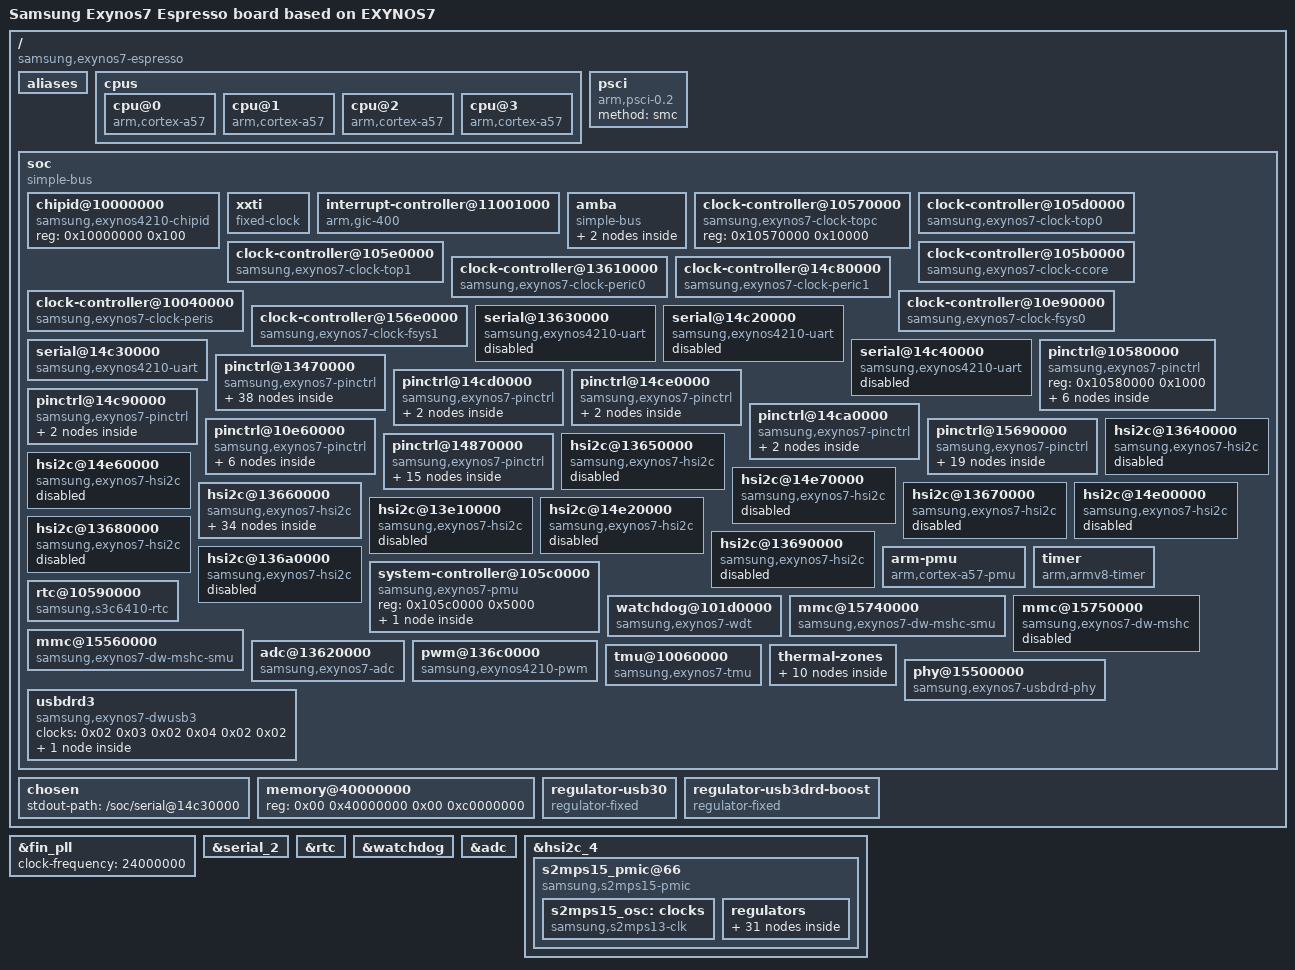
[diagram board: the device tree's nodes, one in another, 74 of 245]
/dts-v1/;

/ {
	compatible = "samsung,exynos7-espresso\0samsung,exynos7";
	interrupt-parent = <0x01>;
	#address-cells = <0x01>;
	#size-cells = <0x01>;
	model = "Samsung Exynos7 Espresso board based on EXYNOS7";

	aliases {
		pinctrl0 = "/soc/pinctrl@10580000";
		pinctrl1 = "/soc/pinctrl@13470000";
		pinctrl2 = "/soc/pinctrl@14cd0000";
		pinctrl3 = "/soc/pinctrl@14ce0000";
		pinctrl4 = "/soc/pinctrl@14c90000";
		pinctrl5 = "/soc/pinctrl@14ca0000";
		pinctrl6 = "/soc/pinctrl@10e60000";
		pinctrl7 = "/soc/pinctrl@15690000";
		pinctrl8 = "/soc/pinctrl@14870000";
		tmuctrl0 = "/soc/tmu@10060000";
		serial0 = "/soc/serial@14c30000";
		mshc0 = "/soc/mmc@15740000";
		mshc2 = "/soc/mmc@15560000";
	};

	cpus {
		#address-cells = <0x01>;
		#size-cells = <0x00>;

		cpu@0 {
			device_type = "cpu";
			compatible = "arm,cortex-a57\0arm,armv8";
			reg = <0x00>;
			enable-method = "psci";
			phandle = <0x17>;
		};

		cpu@1 {
			device_type = "cpu";
			compatible = "arm,cortex-a57\0arm,armv8";
			reg = <0x01>;
			enable-method = "psci";
			phandle = <0x18>;
		};

		cpu@2 {
			device_type = "cpu";
			compatible = "arm,cortex-a57\0arm,armv8";
			reg = <0x02>;
			enable-method = "psci";
			phandle = <0x19>;
		};

		cpu@3 {
			device_type = "cpu";
			compatible = "arm,cortex-a57\0arm,armv8";
			reg = <0x03>;
			enable-method = "psci";
			phandle = <0x1a>;
		};
	};

	psci {
		compatible = "arm,psci-0.2";
		method = "smc";
	};

	soc {
		compatible = "simple-bus";
		#address-cells = <0x01>;
		#size-cells = <0x01>;
		ranges;
		phandle = <0x35>;

		chipid@10000000 {
			compatible = "samsung,exynos4210-chipid";
			reg = <0x10000000 0x100>;
		};

		xxti {
			compatible = "fixed-clock";
			clock-output-names = "fin_pll";
			#clock-cells = <0x00>;
			clock-frequency = <0x16e3600>;
			phandle = <0x03>;
		};

		interrupt-controller@11001000 {
			compatible = "arm,gic-400";
			#interrupt-cells = <0x03>;
			#address-cells = <0x00>;
			interrupt-controller;
			reg = <0x11001000 0x1000 0x11002000 0x1000 0x11004000 0x2000 0x11006000 0x2000>;
			phandle = <0x01>;
		};

		amba {
			compatible = "simple-bus";
			#address-cells = <0x01>;
			#size-cells = <0x01>;
			ranges;

			pdma@10e10000 {
				compatible = "arm,pl330\0arm,primecell";
				reg = <0x10e10000 0x1000>;
				interrupts = <0x00 0xe1 0x04>;
				clocks = <0x02 0x09>;
				clock-names = "apb_pclk";
				#dma-cells = <0x01>;
				#dma-channels = <0x08>;
				#dma-requests = <0x20>;
				phandle = <0x36>;
			};

			pdma@10eb0000 {
				compatible = "arm,pl330\0arm,primecell";
				reg = <0x10eb0000 0x1000>;
				interrupts = <0x00 0xe2 0x04>;
				clocks = <0x02 0x0a>;
				clock-names = "apb_pclk";
				#dma-cells = <0x01>;
				#dma-channels = <0x08>;
				#dma-requests = <0x20>;
				phandle = <0x37>;
			};
		};

		clock-controller@10570000 {
			compatible = "samsung,exynos7-clock-topc";
			reg = <0x10570000 0x10000>;
			#clock-cells = <0x01>;
			phandle = <0x04>;
		};

		clock-controller@105d0000 {
			compatible = "samsung,exynos7-clock-top0";
			reg = <0x105d0000 0xb000>;
			#clock-cells = <0x01>;
			clocks = <0x03 0x04 0x02 0x04 0x03 0x04 0x04 0x04 0x05>;
			clock-names = "fin_pll\0dout_sclk_bus0_pll\0dout_sclk_bus1_pll\0dout_sclk_cc_pll\0dout_sclk_mfc_pll";
			phandle = <0x05>;
		};

		clock-controller@105e0000 {
			compatible = "samsung,exynos7-clock-top1";
			reg = <0x105e0000 0xb000>;
			#clock-cells = <0x01>;
			clocks = <0x03 0x04 0x02 0x04 0x03 0x04 0x04 0x04 0x05>;
			clock-names = "fin_pll\0dout_sclk_bus0_pll\0dout_sclk_bus1_pll\0dout_sclk_cc_pll\0dout_sclk_mfc_pll";
			phandle = <0x06>;
		};

		clock-controller@105b0000 {
			compatible = "samsung,exynos7-clock-ccore";
			reg = <0x105b0000 0xd00>;
			#clock-cells = <0x01>;
			clocks = <0x03 0x04 0x06>;
			clock-names = "fin_pll\0dout_aclk_ccore_133";
			phandle = <0x1c>;
		};

		clock-controller@13610000 {
			compatible = "samsung,exynos7-clock-peric0";
			reg = <0x13610000 0xd00>;
			#clock-cells = <0x01>;
			clocks = <0x03 0x05 0x02 0x05 0x03>;
			clock-names = "fin_pll\0dout_aclk_peric0_66\0sclk_uart0";
			phandle = <0x07>;
		};

		clock-controller@14c80000 {
			compatible = "samsung,exynos7-clock-peric1";
			reg = <0x14c80000 0xd00>;
			#clock-cells = <0x01>;
			clocks = <0x03 0x05 0x01 0x05 0x04 0x05 0x05 0x05 0x06>;
			clock-names = "fin_pll\0dout_aclk_peric1_66\0sclk_uart1\0sclk_uart2\0sclk_uart3";
			phandle = <0x08>;
		};

		clock-controller@10040000 {
			compatible = "samsung,exynos7-clock-peris";
			reg = <0x10040000 0xd00>;
			#clock-cells = <0x01>;
			clocks = <0x03 0x04 0x01>;
			clock-names = "fin_pll\0dout_aclk_peris_66";
			phandle = <0x1e>;
		};

		clock-controller@10e90000 {
			compatible = "samsung,exynos7-clock-fsys0";
			reg = <0x10e90000 0xd00>;
			#clock-cells = <0x01>;
			clocks = <0x03 0x06 0x02 0x06 0x03>;
			clock-names = "fin_pll\0dout_aclk_fsys0_200\0dout_sclk_mmc2";
			phandle = <0x02>;
		};

		clock-controller@156e0000 {
			compatible = "samsung,exynos7-clock-fsys1";
			reg = <0x156e0000 0xd00>;
			#clock-cells = <0x01>;
			clocks = <0x03 0x06 0x01 0x06 0x05 0x06 0x04>;
			clock-names = "fin_pll\0dout_aclk_fsys1_200\0dout_sclk_mmc0\0dout_sclk_mmc1";
			phandle = <0x1f>;
		};

		serial@13630000 {
			compatible = "samsung,exynos4210-uart";
			reg = <0x13630000 0x100>;
			interrupts = <0x00 0x1b8 0x04>;
			clocks = <0x07 0x01 0x07 0x02>;
			clock-names = "uart\0clk_uart_baud0";
			status = "disabled";
			phandle = <0x38>;
		};

		serial@14c20000 {
			compatible = "samsung,exynos4210-uart";
			reg = <0x14c20000 0x100>;
			interrupts = <0x00 0x1c8 0x04>;
			clocks = <0x08 0x01 0x08 0x04>;
			clock-names = "uart\0clk_uart_baud0";
			status = "disabled";
			phandle = <0x39>;
		};

		serial@14c30000 {
			compatible = "samsung,exynos4210-uart";
			reg = <0x14c30000 0x100>;
			interrupts = <0x00 0x1c9 0x04>;
			clocks = <0x08 0x02 0x08 0x05>;
			clock-names = "uart\0clk_uart_baud0";
			status = "okay";
			phandle = <0x3a>;
		};

		serial@14c40000 {
			compatible = "samsung,exynos4210-uart";
			reg = <0x14c40000 0x100>;
			interrupts = <0x00 0x1ca 0x04>;
			clocks = <0x08 0x03 0x08 0x06>;
			clock-names = "uart\0clk_uart_baud0";
			status = "disabled";
			phandle = <0x3b>;
		};

		pinctrl@10580000 {
			compatible = "samsung,exynos7-pinctrl";
			reg = <0x10580000 0x1000>;
			phandle = <0x3c>;

			wakeup-interrupt-controller {
				compatible = "samsung,exynos7-wakeup-eint";
				interrupt-parent = <0x01>;
				interrupts = <0x00 0x10 0x04>;
			};

			gpa0 {
				gpio-controller;
				#gpio-cells = <0x02>;
				interrupt-controller;
				interrupt-parent = <0x01>;
				#interrupt-cells = <0x02>;
				interrupts = <0x00 0x00 0x04 0x00 0x01 0x04 0x00 0x02 0x04 0x00 0x03 0x04 0x00 0x04 0x04 0x00 0x05 0x04 0x00 0x06 0x04 0x00 0x07 0x04>;
				phandle = <0x0e>;
			};

			gpa1 {
				gpio-controller;
				#gpio-cells = <0x02>;
				interrupt-controller;
				interrupt-parent = <0x01>;
				#interrupt-cells = <0x02>;
				interrupts = <0x00 0x08 0x04 0x00 0x09 0x04 0x00 0x0a 0x04 0x00 0x0b 0x04 0x00 0x0c 0x04 0x00 0x0d 0x04 0x00 0x0e 0x04 0x00 0x0f 0x04>;
				phandle = <0x3d>;
			};

			gpa2 {
				gpio-controller;
				#gpio-cells = <0x02>;
				interrupt-controller;
				#interrupt-cells = <0x02>;
				phandle = <0x3e>;
			};

			gpa3 {
				gpio-controller;
				#gpio-cells = <0x02>;
				interrupt-controller;
				#interrupt-cells = <0x02>;
				phandle = <0x3f>;
			};

			pmic-irq {
				samsung,pins = "gpa0-2";
				samsung,pin-pud = <0x03>;
				samsung,pin-drv = <0x03>;
				phandle = <0x0f>;
			};
		};

		pinctrl@13470000 {
			compatible = "samsung,exynos7-pinctrl";
			reg = <0x13470000 0x1000>;
			interrupts = <0x00 0x17f 0x04>;
			phandle = <0x40>;

			gpb0 {
				gpio-controller;
				#gpio-cells = <0x02>;
				interrupt-controller;
				#interrupt-cells = <0x02>;
				phandle = <0x41>;
			};

			gpc0 {
				gpio-controller;
				#gpio-cells = <0x02>;
				interrupt-controller;
				#interrupt-cells = <0x02>;
				phandle = <0x42>;
			};

			gpc1 {
				gpio-controller;
				#gpio-cells = <0x02>;
				interrupt-controller;
				#interrupt-cells = <0x02>;
				phandle = <0x43>;
			};

			gpc2 {
				gpio-controller;
				#gpio-cells = <0x02>;
				interrupt-controller;
				#interrupt-cells = <0x02>;
				phandle = <0x44>;
			};

			gpc3 {
				gpio-controller;
				#gpio-cells = <0x02>;
				interrupt-controller;
				#interrupt-cells = <0x02>;
				phandle = <0x45>;
			};

			gpd0 {
				gpio-controller;
				#gpio-cells = <0x02>;
				interrupt-controller;
				#interrupt-cells = <0x02>;
				phandle = <0x46>;
			};

			gpd1 {
				gpio-controller;
				#gpio-cells = <0x02>;
				interrupt-controller;
				#interrupt-cells = <0x02>;
				phandle = <0x47>;
			};

			gpd2 {
				gpio-controller;
				#gpio-cells = <0x02>;
				interrupt-controller;
				#interrupt-cells = <0x02>;
				phandle = <0x48>;
			};

			gpd4 {
				gpio-controller;
				#gpio-cells = <0x02>;
				interrupt-controller;
				#interrupt-cells = <0x02>;
				phandle = <0x49>;
			};

			gpd5 {
				gpio-controller;
				#gpio-cells = <0x02>;
				interrupt-controller;
				#interrupt-cells = <0x02>;
				phandle = <0x4a>;
			};

			gpd6 {
				gpio-controller;
				#gpio-cells = <0x02>;
				interrupt-controller;
				#interrupt-cells = <0x02>;
				phandle = <0x4b>;
			};

			gpd7 {
				gpio-controller;
				#gpio-cells = <0x02>;
				interrupt-controller;
				#interrupt-cells = <0x02>;
				phandle = <0x4c>;
			};

			gpd8 {
				gpio-controller;
				#gpio-cells = <0x02>;
				interrupt-controller;
				#interrupt-cells = <0x02>;
				phandle = <0x4d>;
			};

			gpg0 {
				gpio-controller;
				#gpio-cells = <0x02>;
				interrupt-controller;
				#interrupt-cells = <0x02>;
				phandle = <0x4e>;
			};

			gpg3 {
				gpio-controller;
				#gpio-cells = <0x02>;
				interrupt-controller;
				#interrupt-cells = <0x02>;
				phandle = <0x4f>;
			};

			hs-i2c10-bus {
				samsung,pins = "gpb0-1\0gpb0-0";
				samsung,pin-function = <0x02>;
				samsung,pin-pud = <0x03>;
				samsung,pin-drv = <0x00>;
				phandle = <0x15>;
			};

			hs-i2c11-bus {
				samsung,pins = "gpb0-3\0gpb0-2";
				samsung,pin-function = <0x02>;
				samsung,pin-pud = <0x03>;
				samsung,pin-drv = <0x00>;
				phandle = <0x16>;
			};

			hs-i2c2-bus {
				samsung,pins = "gpd0-3\0gpd0-2";
				samsung,pin-function = <0x03>;
				samsung,pin-pud = <0x03>;
				samsung,pin-drv = <0x00>;
				phandle = <0x0b>;
			};

			uart0-data {
				samsung,pins = "gpd0-0\0gpd0-1";
				samsung,pin-function = <0x02>;
				samsung,pin-pud = <0x00>;
				samsung,pin-drv = <0x00>;
				phandle = <0x50>;
			};

			uart0-fctl {
				samsung,pins = "gpd0-2\0gpd0-3";
				samsung,pin-function = <0x02>;
				samsung,pin-pud = <0x00>;
				samsung,pin-drv = <0x00>;
				phandle = <0x51>;
			};

			uart2-data {
				samsung,pins = "gpd1-4\0gpd1-5";
				samsung,pin-function = <0x02>;
				samsung,pin-pud = <0x00>;
				samsung,pin-drv = <0x00>;
				phandle = <0x52>;
			};

			hs-i2c3-bus {
				samsung,pins = "gpd1-3\0gpd1-2";
				samsung,pin-function = <0x03>;
				samsung,pin-pud = <0x03>;
				samsung,pin-drv = <0x00>;
				phandle = <0x0c>;
			};

			uart1-data {
				samsung,pins = "gpd1-0\0gpd1-1";
				samsung,pin-function = <0x02>;
				samsung,pin-pud = <0x00>;
				samsung,pin-drv = <0x00>;
				phandle = <0x53>;
			};

			uart1-fctl {
				samsung,pins = "gpd1-2\0gpd1-3";
				samsung,pin-function = <0x02>;
				samsung,pin-pud = <0x00>;
				samsung,pin-drv = <0x00>;
				phandle = <0x54>;
			};

			hs-i2c0-bus {
				samsung,pins = "gpd2-1\0gpd2-0";
				samsung,pin-function = <0x02>;
				samsung,pin-pud = <0x03>;
				samsung,pin-drv = <0x00>;
				phandle = <0x09>;
			};

			hs-i2c1-bus {
				samsung,pins = "gpd2-3\0gpd2-2";
				samsung,pin-function = <0x02>;
				samsung,pin-pud = <0x03>;
				samsung,pin-drv = <0x00>;
				phandle = <0x0a>;
			};

			hs-i2c9-bus {
				samsung,pins = "gpd2-7\0gpd2-6";
				samsung,pin-function = <0x03>;
				samsung,pin-pud = <0x03>;
				samsung,pin-drv = <0x00>;
				phandle = <0x14>;
			};

			pwm0-out {
				samsung,pins = "gpd2-4";
				samsung,pin-function = <0x02>;
				samsung,pin-pud = <0x00>;
				samsung,pin-drv = <0x00>;
				phandle = <0x55>;
			};

			pwm1-out {
				samsung,pins = "gpd2-5";
				samsung,pin-function = <0x02>;
				samsung,pin-pud = <0x00>;
				samsung,pin-drv = <0x00>;
				phandle = <0x56>;
			};

			pwm2-out {
				samsung,pins = "gpd2-6";
				samsung,pin-function = <0x02>;
				samsung,pin-pud = <0x00>;
				samsung,pin-drv = <0x00>;
				phandle = <0x57>;
			};

			pwm3-out {
				samsung,pins = "gpd2-7";
				samsung,pin-function = <0x02>;
				samsung,pin-pud = <0x00>;
				samsung,pin-drv = <0x00>;
				phandle = <0x58>;
			};

			hs-i2c8-bus {
				samsung,pins = "gpd5-3\0gpd5-2";
				samsung,pin-function = <0x03>;
				samsung,pin-pud = <0x03>;
				samsung,pin-drv = <0x00>;
				phandle = <0x13>;
			};

			uart3-data {
				samsung,pins = "gpd5-0\0gpd5-1";
				samsung,pin-function = <0x03>;
				samsung,pin-pud = <0x00>;
				samsung,pin-drv = <0x00>;
				phandle = <0x59>;
			};

			spi2-bus {
				samsung,pins = "gpd5-0\0gpd5-1\0gpd5-2\0gpd5-3";
				samsung,pin-function = <0x02>;
				samsung,pin-pud = <0x03>;
				samsung,pin-drv = <0x00>;
				phandle = <0x5a>;
			};

			spi1-bus {
				samsung,pins = "gpd6-2\0gpd6-3\0gpd6-4\0gpd6-5";
				samsung,pin-function = <0x02>;
				samsung,pin-pud = <0x03>;
				samsung,pin-drv = <0x00>;
				phandle = <0x5b>;
			};

			spi0-bus {
				samsung,pins = "gpd8-0\0gpd8-1\0gpd6-0\0gpd6-1";
				samsung,pin-function = <0x02>;
				samsung,pin-pud = <0x03>;
				samsung,pin-drv = <0x00>;
				phandle = <0x5c>;
			};

			hs-i2c4-bus {
				samsung,pins = "gpg3-1\0gpg3-0";
				samsung,pin-function = <0x02>;
				samsung,pin-pud = <0x03>;
				samsung,pin-drv = <0x00>;
				phandle = <0x0d>;
			};

			hs-i2c5-bus {
				samsung,pins = "gpg3-3\0gpg3-2";
				samsung,pin-function = <0x02>;
				samsung,pin-pud = <0x03>;
				samsung,pin-drv = <0x00>;
				phandle = <0x10>;
			};
		};

		pinctrl@14cd0000 {
			compatible = "samsung,exynos7-pinctrl";
			reg = <0x14cd0000 0x1000>;
			interrupts = <0x00 0x1d9 0x04>;
			phandle = <0x5d>;

			gpj0 {
				gpio-controller;
				#gpio-cells = <0x02>;
				interrupt-controller;
				#interrupt-cells = <0x02>;
				phandle = <0x5e>;
			};

			hs-i2c6-bus {
				samsung,pins = "gpj0-1\0gpj0-0";
				samsung,pin-function = <0x02>;
				samsung,pin-pud = <0x03>;
				samsung,pin-drv = <0x00>;
				phandle = <0x11>;
			};
		};

		pinctrl@14ce0000 {
			compatible = "samsung,exynos7-pinctrl";
			reg = <0x14ce0000 0x1000>;
			interrupts = <0x00 0x1da 0x04>;
			phandle = <0x5f>;

			gpj1 {
				gpio-controller;
				#gpio-cells = <0x02>;
				interrupt-controller;
				#interrupt-cells = <0x02>;
				phandle = <0x60>;
			};

			hs-i2c7-bus {
				samsung,pins = "gpj1-1\0gpj1-0";
				samsung,pin-function = <0x02>;
				samsung,pin-pud = <0x03>;
				samsung,pin-drv = <0x00>;
				phandle = <0x12>;
			};
		};

		pinctrl@14c90000 {
			compatible = "samsung,exynos7-pinctrl";
			reg = <0x14c90000 0x1000>;
			interrupts = <0x00 0x1db 0x04>;
			phandle = <0x61>;

			gpg4 {
				gpio-controller;
				#gpio-cells = <0x02>;
				interrupt-controller;
				#interrupt-cells = <0x02>;
				phandle = <0x62>;
			};

			spi3-bus {
				samsung,pins = "gpg4-0\0gpg4-1\0gpg4-2\0gpg4-3";
				samsung,pin-function = <0x02>;
				samsung,pin-pud = <0x03>;
				samsung,pin-drv = <0x00>;
				phandle = <0x63>;
			};
		};

		pinctrl@14ca0000 {
			compatible = "samsung,exynos7-pinctrl";
			reg = <0x14ca0000 0x1000>;
			interrupts = <0x00 0x1dc 0x04>;
			phandle = <0x64>;

			gpv7 {
				gpio-controller;
				#gpio-cells = <0x02>;
				interrupt-controller;
				#interrupt-cells = <0x02>;
				phandle = <0x65>;
			};

			spi4-bus {
				samsung,pins = "gpv7-0\0gpv7-1\0gpv7-2\0gpv7-3";
				samsung,pin-function = <0x02>;
				samsung,pin-pud = <0x03>;
				samsung,pin-drv = <0x00>;
				phandle = <0x66>;
			};
		};

		pinctrl@10e60000 {
			compatible = "samsung,exynos7-pinctrl";
			reg = <0x10e60000 0x1000>;
			interrupts = <0x00 0xdd 0x04>;
			phandle = <0x67>;

			gpr4 {
				gpio-controller;
				#gpio-cells = <0x02>;
				interrupt-controller;
				#interrupt-cells = <0x02>;
				phandle = <0x68>;
			};

			sd2-clk {
				samsung,pins = "gpr4-0";
				samsung,pin-function = <0x02>;
				samsung,pin-pud = <0x00>;
				samsung,pin-drv = <0x03>;
				phandle = <0x26>;
			};

			sd2-cmd {
				samsung,pins = "gpr4-1";
				samsung,pin-function = <0x02>;
				samsung,pin-pud = <0x00>;
				samsung,pin-drv = <0x03>;
				phandle = <0x27>;
			};

			sd2-cd {
				samsung,pins = "gpr4-2";
				samsung,pin-function = <0x02>;
				samsung,pin-pud = <0x03>;
				samsung,pin-drv = <0x03>;
				phandle = <0x28>;
			};

			sd2-bus-width1 {
				samsung,pins = "gpr4-3";
				samsung,pin-function = <0x02>;
				samsung,pin-pud = <0x03>;
				samsung,pin-drv = <0x03>;
				phandle = <0x29>;
			};

			sd2-bus-width4 {
				samsung,pins = "gpr4-4\0gpr4-5\0gpr4-6";
				samsung,pin-function = <0x02>;
				samsung,pin-pud = <0x03>;
				samsung,pin-drv = <0x03>;
				phandle = <0x2a>;
			};
		};

		pinctrl@15690000 {
			compatible = "samsung,exynos7-pinctrl";
			reg = <0x15690000 0x1000>;
			interrupts = <0x00 0xcb 0x04>;
			phandle = <0x69>;

			gpr0 {
				gpio-controller;
				#gpio-cells = <0x02>;
				interrupt-controller;
				#interrupt-cells = <0x02>;
				phandle = <0x6a>;
			};

			gpr1 {
				gpio-controller;
				#gpio-cells = <0x02>;
				interrupt-controller;
				#interrupt-cells = <0x02>;
				phandle = <0x6b>;
			};

			gpr2 {
				gpio-controller;
				#gpio-cells = <0x02>;
				interrupt-controller;
				#interrupt-cells = <0x02>;
				phandle = <0x6c>;
			};

			gpr3 {
				gpio-controller;
				#gpio-cells = <0x02>;
				interrupt-controller;
				#interrupt-cells = <0x02>;
				phandle = <0x6d>;
			};

			sd0-clk {
				samsung,pins = "gpr0-0";
				samsung,pin-function = <0x02>;
				samsung,pin-pud = <0x00>;
				samsung,pin-drv = <0x04>;
				phandle = <0x20>;
			};

			sd0-cmd {
				samsung,pins = "gpr0-1";
				samsung,pin-function = <0x02>;
				samsung,pin-pud = <0x03>;
				samsung,pin-drv = <0x04>;
				phandle = <0x21>;
			};

			sd0-ds {
				samsung,pins = "gpr0-2";
				samsung,pin-function = <0x02>;
				samsung,pin-pud = <0x01>;
				samsung,pin-drv = <0x04>;
				phandle = <0x6e>;
			};

			sd0-qrdy {
				samsung,pins = "gpr0-3";
				samsung,pin-function = <0x02>;
				samsung,pin-pud = <0x01>;
				samsung,pin-drv = <0x04>;
				phandle = <0x22>;
			};

			sd0-bus-width1 {
				samsung,pins = "gpr1-0";
				samsung,pin-function = <0x02>;
				samsung,pin-pud = <0x03>;
				samsung,pin-drv = <0x04>;
				phandle = <0x23>;
			};

			sd0-bus-width4 {
				samsung,pins = "gpr1-1\0gpr1-2\0gpr1-3";
				samsung,pin-function = <0x02>;
				samsung,pin-pud = <0x03>;
				samsung,pin-drv = <0x04>;
				phandle = <0x24>;
			};

			sd0-bus-width8 {
				samsung,pins = "gpr1-4\0gpr1-5\0gpr1-6\0gpr1-7";
				samsung,pin-function = <0x02>;
				samsung,pin-pud = <0x03>;
				samsung,pin-drv = <0x04>;
				phandle = <0x25>;
			};

			sd1-clk {
				samsung,pins = "gpr2-0";
				samsung,pin-function = <0x02>;
				samsung,pin-pud = <0x00>;
				samsung,pin-drv = <0x02>;
				phandle = <0x6f>;
			};

			sd1-cmd {
				samsung,pins = "gpr2-1";
				samsung,pin-function = <0x02>;
				samsung,pin-pud = <0x00>;
				samsung,pin-drv = <0x02>;
				phandle = <0x70>;
			};

			sd1-ds {
				samsung,pins = "gpr2-2";
				samsung,pin-function = <0x02>;
				samsung,pin-pud = <0x01>;
				samsung,pin-drv = <0x06>;
				phandle = <0x71>;
			};

			sd1-qrdy {
				samsung,pins = "gpr2-3";
				samsung,pin-function = <0x02>;
				samsung,pin-pud = <0x01>;
				samsung,pin-drv = <0x06>;
				phandle = <0x72>;
			};

			sd1-int {
				samsung,pins = "gpr2-4";
				samsung,pin-function = <0x02>;
				samsung,pin-pud = <0x01>;
				samsung,pin-drv = <0x06>;
				phandle = <0x73>;
			};

			sd1-bus-width1 {
				samsung,pins = "gpr3-0";
				samsung,pin-function = <0x02>;
				samsung,pin-pud = <0x03>;
				samsung,pin-drv = <0x02>;
				phandle = <0x74>;
			};

			sd1-bus-width4 {
				samsung,pins = "gpr3-1\0gpr3-2\0gpr3-3";
				samsung,pin-function = <0x02>;
				samsung,pin-pud = <0x03>;
				samsung,pin-drv = <0x02>;
				phandle = <0x75>;
			};

			sd1-bus-width8 {
				samsung,pins = "gpr3-4\0gpr3-5\0gpr3-6\0gpr3-7";
				samsung,pin-function = <0x02>;
				samsung,pin-pud = <0x03>;
				samsung,pin-drv = <0x02>;
				phandle = <0x76>;
			};
		};

		pinctrl@14870000 {
			compatible = "samsung,exynos7-pinctrl";
			reg = <0x14870000 0x1000>;
			interrupts = <0x00 0x180 0x04>;
			phandle = <0x77>;

			gpf0 {
				gpio-controller;
				#gpio-cells = <0x02>;
				interrupt-controller;
				#interrupt-cells = <0x02>;
				phandle = <0x78>;
			};

			gpf1 {
				gpio-controller;
				#gpio-cells = <0x02>;
				interrupt-controller;
				#interrupt-cells = <0x02>;
				phandle = <0x79>;
			};

			gpf2 {
				gpio-controller;
				#gpio-cells = <0x02>;
				interrupt-controller;
				#interrupt-cells = <0x02>;
				phandle = <0x7a>;
			};

			gpf3 {
				gpio-controller;
				#gpio-cells = <0x02>;
				interrupt-controller;
				#interrupt-cells = <0x02>;
				phandle = <0x7b>;
			};

			gpf4 {
				gpio-controller;
				#gpio-cells = <0x02>;
				interrupt-controller;
				#interrupt-cells = <0x02>;
				phandle = <0x33>;
			};

			gpf5 {
				gpio-controller;
				#gpio-cells = <0x02>;
				interrupt-controller;
				#interrupt-cells = <0x02>;
				phandle = <0x7c>;
			};

			gpg1 {
				gpio-controller;
				#gpio-cells = <0x02>;
				interrupt-controller;
				#interrupt-cells = <0x02>;
				phandle = <0x7d>;
			};

			gpg2 {
				gpio-controller;
				#gpio-cells = <0x02>;
				interrupt-controller;
				#interrupt-cells = <0x02>;
				phandle = <0x7e>;
			};

			gph1 {
				gpio-controller;
				#gpio-cells = <0x02>;
				interrupt-controller;
				#interrupt-cells = <0x02>;
				phandle = <0x31>;
			};

			gpv6 {
				gpio-controller;
				#gpio-cells = <0x02>;
				interrupt-controller;
				#interrupt-cells = <0x02>;
				phandle = <0x7f>;
			};

			spi5-bus {
				samsung,pins = "gpf2-0\0gpf2-1\0gpf2-2\0gpf2-3";
				samsung,pin-function = <0x02>;
				samsung,pin-pud = <0x03>;
				samsung,pin-drv = <0x00>;
				phandle = <0x80>;
			};

			ufs-refclk-out {
				samsung,pins = "gpg2-4";
				samsung,pin-function = <0x02>;
				samsung,pin-pud = <0x00>;
				samsung,pin-drv = <0x02>;
				phandle = <0x81>;
			};

			ufs-rst-n {
				samsung,pins = "gph1-5";
				samsung,pin-function = <0x02>;
				samsung,pin-pud = <0x03>;
				samsung,pin-drv = <0x00>;
				phandle = <0x82>;
			};

			usb30-vbus-en {
				samsung,pins = "gph1-1";
				samsung,pin-function = <0x01>;
				samsung,pin-pud = <0x00>;
				samsung,pin-drv = <0x00>;
				phandle = <0x32>;
			};

			usb3drd-boost-en {
				samsung,pins = "gpf4-1";
				samsung,pin-function = <0x01>;
				samsung,pin-pud = <0x00>;
				samsung,pin-drv = <0x00>;
				phandle = <0x34>;
			};
		};

		hsi2c@13640000 {
			compatible = "samsung,exynos7-hsi2c";
			reg = <0x13640000 0x1000>;
			interrupts = <0x00 0x1b9 0x04>;
			#address-cells = <0x01>;
			#size-cells = <0x00>;
			pinctrl-names = "default";
			pinctrl-0 = <0x09>;
			clocks = <0x07 0x03>;
			clock-names = "hsi2c";
			status = "disabled";
			phandle = <0x83>;
		};

		hsi2c@13650000 {
			compatible = "samsung,exynos7-hsi2c";
			reg = <0x13650000 0x1000>;
			interrupts = <0x00 0x1ba 0x04>;
			#address-cells = <0x01>;
			#size-cells = <0x00>;
			pinctrl-names = "default";
			pinctrl-0 = <0x0a>;
			clocks = <0x07 0x04>;
			clock-names = "hsi2c";
			status = "disabled";
			phandle = <0x84>;
		};

		hsi2c@14e60000 {
			compatible = "samsung,exynos7-hsi2c";
			reg = <0x14e60000 0x1000>;
			interrupts = <0x00 0x1cb 0x04>;
			#address-cells = <0x01>;
			#size-cells = <0x00>;
			pinctrl-names = "default";
			pinctrl-0 = <0x0b>;
			clocks = <0x08 0x07>;
			clock-names = "hsi2c";
			status = "disabled";
			phandle = <0x85>;
		};

		hsi2c@14e70000 {
			compatible = "samsung,exynos7-hsi2c";
			reg = <0x14e70000 0x1000>;
			interrupts = <0x00 0x1cc 0x04>;
			#address-cells = <0x01>;
			#size-cells = <0x00>;
			pinctrl-names = "default";
			pinctrl-0 = <0x0c>;
			clocks = <0x08 0x08>;
			clock-names = "hsi2c";
			status = "disabled";
			phandle = <0x86>;
		};

		hsi2c@13660000 {
			compatible = "samsung,exynos7-hsi2c";
			reg = <0x13660000 0x1000>;
			interrupts = <0x00 0x1bb 0x04>;
			#address-cells = <0x01>;
			#size-cells = <0x00>;
			pinctrl-names = "default";
			pinctrl-0 = <0x0d>;
			clocks = <0x07 0x05>;
			clock-names = "hsi2c";
			status = "okay";
			samsung,i2c-sda-delay = <0x64>;
			samsung,i2c-max-bus-freq = <0x30d40>;
			phandle = <0x87>;

			s2mps15_pmic@66 {
				compatible = "samsung,s2mps15-pmic";
				reg = <0x66>;
				interrupts = <0x02 0x00>;
				interrupt-parent = <0x0e>;
				pinctrl-names = "default";
				pinctrl-0 = <0x0f>;
				wakeup-source;

				clocks {
					compatible = "samsung,s2mps13-clk";
					#clock-cells = <0x01>;
					clock-output-names = "s2mps13_ap\0s2mps13_cp\0s2mps13_bt";
					phandle = <0x1d>;
				};

				regulators {

					LDO1 {
						regulator-name = "vdd_ldo1";
						regulator-min-microvolt = <0x7a120>;
						regulator-max-microvolt = <0xdbba0>;
						regulator-always-on;
						regulator-enable-ramp-delay = <0x7d>;
						phandle = <0x88>;
					};

					LDO2 {
						regulator-name = "vqmmc-sdcard";
						regulator-min-microvolt = <0x18b820>;
						regulator-max-microvolt = <0x325aa0>;
						regulator-always-on;
						regulator-enable-ramp-delay = <0x7d>;
						phandle = <0x2c>;
					};

					LDO3 {
						regulator-name = "vdd_ldo3";
						regulator-min-microvolt = <0x18b820>;
						regulator-max-microvolt = <0x1e3660>;
						regulator-always-on;
						regulator-boot-on;
						regulator-enable-ramp-delay = <0x7d>;
						phandle = <0x89>;
					};

					LDO4 {
						regulator-name = "vdd_ldo4";
						regulator-min-microvolt = <0xc3500>;
						regulator-max-microvolt = <0x10eff0>;
						regulator-always-on;
						regulator-enable-ramp-delay = <0x7d>;
						phandle = <0x8a>;
					};

					LDO5 {
						regulator-name = "vdd_ldo5";
						regulator-min-microvolt = <0x18b820>;
						regulator-max-microvolt = <0x1e3660>;
						regulator-always-on;
						regulator-enable-ramp-delay = <0x7d>;
						phandle = <0x8b>;
					};

					LDO6 {
						regulator-name = "vdd_ldo6";
						regulator-min-microvolt = <0x225510>;
						regulator-max-microvolt = <0x325aa0>;
						regulator-enable-ramp-delay = <0x7d>;
						phandle = <0x8c>;
					};

					LDO7 {
						regulator-name = "vdd_ldo7";
						regulator-min-microvolt = <0xaae60>;
						regulator-max-microvolt = <0x118c30>;
						regulator-enable-ramp-delay = <0x7d>;
						phandle = <0x8d>;
					};

					LDO8 {
						regulator-name = "vdd_ldo8";
						regulator-min-microvolt = <0xaae60>;
						regulator-max-microvolt = <0xf4240>;
						regulator-enable-ramp-delay = <0x7d>;
						phandle = <0x8e>;
					};

					LDO9 {
						regulator-name = "vdd_ldo9";
						regulator-min-microvolt = <0xaae60>;
						regulator-max-microvolt = <0xf4240>;
						regulator-enable-ramp-delay = <0x7d>;
						phandle = <0x8f>;
					};

					LDO10 {
						regulator-name = "vdd_ldo10";
						regulator-min-microvolt = <0xaae60>;
						regulator-max-microvolt = <0xf4240>;
						regulator-enable-ramp-delay = <0x7d>;
						phandle = <0x90>;
					};

					LDO11 {
						regulator-name = "vdd_ldo11";
						regulator-min-microvolt = <0xf4240>;
						regulator-max-microvolt = <0x13d620>;
						regulator-always-on;
						regulator-enable-ramp-delay = <0x7d>;
						phandle = <0x91>;
					};

					LDO12 {
						regulator-name = "vdd_ldo12";
						regulator-min-microvolt = <0xf4240>;
						regulator-max-microvolt = <0x13d620>;
						regulator-enable-ramp-delay = <0x7d>;
						phandle = <0x92>;
					};

					LDO13 {
						regulator-name = "vdd_ldo13";
						regulator-min-microvolt = <0xf4240>;
						regulator-max-microvolt = <0x13d620>;
						regulator-always-on;
						regulator-enable-ramp-delay = <0x7d>;
						phandle = <0x93>;
					};

					LDO14 {
						regulator-name = "vdd_ldo14";
						regulator-min-microvolt = <0x1b7740>;
						regulator-max-microvolt = <0x337f98>;
						regulator-enable-ramp-delay = <0x7d>;
						phandle = <0x94>;
					};

					LDO17 {
						regulator-name = "vmmc-sdcard";
						regulator-min-microvolt = <0x1b7740>;
						regulator-max-microvolt = <0x337f98>;
						regulator-enable-ramp-delay = <0x7d>;
						phandle = <0x2b>;
					};

					LDO18 {
						regulator-name = "vdd_ldo18";
						regulator-min-microvolt = <0x16e360>;
						regulator-max-microvolt = <0x22b6b8>;
						regulator-enable-ramp-delay = <0x7d>;
						phandle = <0x95>;
					};

					LDO19 {
						regulator-name = "vdd_ldo19";
						regulator-min-microvolt = <0x1b7740>;
						regulator-max-microvolt = <0x337f98>;
						regulator-enable-ramp-delay = <0x7d>;
						phandle = <0x96>;
					};

					LDO21 {
						regulator-name = "vdd_ldo21";
						regulator-min-microvolt = <0x1b7740>;
						regulator-max-microvolt = <0x337f98>;
						regulator-enable-ramp-delay = <0x7d>;
						phandle = <0x97>;
					};

					LDO23 {
						regulator-name = "vdd_ldo23";
						regulator-min-microvolt = <0x16e360>;
						regulator-max-microvolt = <0x22b6b8>;
						regulator-enable-ramp-delay = <0x7d>;
						phandle = <0x98>;
					};

					LDO25 {
						regulator-name = "vdd_ldo25";
						regulator-min-microvolt = <0x1b7740>;
						regulator-max-microvolt = <0x337f98>;
						regulator-enable-ramp-delay = <0x7d>;
						phandle = <0x99>;
					};

					LDO26 {
						regulator-name = "vdd_ldo26";
						regulator-min-microvolt = <0xaae60>;
						regulator-max-microvolt = <0x166e30>;
						regulator-enable-ramp-delay = <0x7d>;
						phandle = <0x9a>;
					};

					LDO27 {
						regulator-name = "vdd_ldo27";
						regulator-min-microvolt = <0x16e360>;
						regulator-max-microvolt = <0x22b6b8>;
						regulator-enable-ramp-delay = <0x7d>;
						phandle = <0x9b>;
					};

					BUCK1 {
						regulator-name = "vdd_mif";
						regulator-min-microvolt = <0x7a120>;
						regulator-max-microvolt = <0x124f80>;
						regulator-always-on;
						regulator-boot-on;
						regulator-ramp-delay = <0x61a8>;
						regulator-enable-ramp-delay = <0xfa>;
						phandle = <0x9c>;
					};

					BUCK2 {
						regulator-name = "vdd_atlas";
						regulator-min-microvolt = <0x7a120>;
						regulator-max-microvolt = <0x124f80>;
						regulator-always-on;
						regulator-boot-on;
						regulator-ramp-delay = <0x30d4>;
						regulator-enable-ramp-delay = <0xfa>;
						phandle = <0x9d>;
					};

					BUCK4 {
						regulator-name = "vdd_int";
						regulator-min-microvolt = <0x7a120>;
						regulator-max-microvolt = <0x124f80>;
						regulator-always-on;
						regulator-boot-on;
						regulator-ramp-delay = <0x30d4>;
						regulator-enable-ramp-delay = <0xfa>;
						phandle = <0x9e>;
					};

					BUCK5 {
						regulator-name = "vdd_buck5";
						regulator-min-microvolt = <0x7a120>;
						regulator-max-microvolt = <0x13d620>;
						regulator-ramp-delay = <0x61a8>;
						regulator-enable-ramp-delay = <0xfa>;
						phandle = <0x9f>;
					};

					BUCK6 {
						regulator-name = "vdd_g3d";
						regulator-min-microvolt = <0x7a120>;
						regulator-max-microvolt = <0x155cc0>;
						regulator-ramp-delay = <0x30d4>;
						regulator-enable-ramp-delay = <0xfa>;
						phandle = <0xa0>;
					};

					BUCK7 {
						regulator-name = "vdd_buck7";
						regulator-min-microvolt = <0xf4240>;
						regulator-max-microvolt = <0x16e360>;
						regulator-always-on;
						regulator-ramp-delay = <0x61a8>;
						regulator-enable-ramp-delay = <0xfa>;
						phandle = <0xa1>;
					};

					BUCK8 {
						regulator-name = "vdd_buck8";
						regulator-min-microvolt = <0xf4240>;
						regulator-max-microvolt = <0x16e360>;
						regulator-always-on;
						regulator-ramp-delay = <0x61a8>;
						regulator-enable-ramp-delay = <0xfa>;
						phandle = <0xa2>;
					};

					BUCK9 {
						regulator-name = "vdd_buck9";
						regulator-min-microvolt = <0x1b7740>;
						regulator-max-microvolt = <0x200b20>;
						regulator-always-on;
						regulator-ramp-delay = <0x61a8>;
						regulator-enable-ramp-delay = <0xfa>;
						phandle = <0xa3>;
					};

					BUCK10 {
						regulator-name = "vdd_buck10";
						regulator-min-microvolt = <0xf4240>;
						regulator-max-microvolt = <0x2dc6c0>;
						regulator-always-on;
						regulator-ramp-delay = <0x61a8>;
						regulator-enable-ramp-delay = <0xfa>;
						phandle = <0xa4>;
					};
				};
			};
		};

		hsi2c@13670000 {
			compatible = "samsung,exynos7-hsi2c";
			reg = <0x13670000 0x1000>;
			interrupts = <0x00 0x1bc 0x04>;
			#address-cells = <0x01>;
			#size-cells = <0x00>;
			pinctrl-names = "default";
			pinctrl-0 = <0x10>;
			clocks = <0x07 0x06>;
			clock-names = "hsi2c";
			status = "disabled";
			phandle = <0xa5>;
		};

		hsi2c@14e00000 {
			compatible = "samsung,exynos7-hsi2c";
			reg = <0x14e00000 0x1000>;
			interrupts = <0x00 0x1cd 0x04>;
			#address-cells = <0x01>;
			#size-cells = <0x00>;
			pinctrl-names = "default";
			pinctrl-0 = <0x11>;
			clocks = <0x08 0x09>;
			clock-names = "hsi2c";
			status = "disabled";
			phandle = <0xa6>;
		};

		hsi2c@13e10000 {
			compatible = "samsung,exynos7-hsi2c";
			reg = <0x13e10000 0x1000>;
			interrupts = <0x00 0x1ce 0x04>;
			#address-cells = <0x01>;
			#size-cells = <0x00>;
			pinctrl-names = "default";
			pinctrl-0 = <0x12>;
			clocks = <0x08 0x0a>;
			clock-names = "hsi2c";
			status = "disabled";
			phandle = <0xa7>;
		};

		hsi2c@14e20000 {
			compatible = "samsung,exynos7-hsi2c";
			reg = <0x14e20000 0x1000>;
			interrupts = <0x00 0x1cf 0x04>;
			#address-cells = <0x01>;
			#size-cells = <0x00>;
			pinctrl-names = "default";
			pinctrl-0 = <0x13>;
			clocks = <0x08 0x0b>;
			clock-names = "hsi2c";
			status = "disabled";
			phandle = <0xa8>;
		};

		hsi2c@13680000 {
			compatible = "samsung,exynos7-hsi2c";
			reg = <0x13680000 0x1000>;
			interrupts = <0x00 0x1bd 0x04>;
			#address-cells = <0x01>;
			#size-cells = <0x00>;
			pinctrl-names = "default";
			pinctrl-0 = <0x14>;
			clocks = <0x07 0x07>;
			clock-names = "hsi2c";
			status = "disabled";
			phandle = <0xa9>;
		};

		hsi2c@13690000 {
			compatible = "samsung,exynos7-hsi2c";
			reg = <0x13690000 0x1000>;
			interrupts = <0x00 0x1be 0x04>;
			#address-cells = <0x01>;
			#size-cells = <0x00>;
			pinctrl-names = "default";
			pinctrl-0 = <0x15>;
			clocks = <0x07 0x08>;
			clock-names = "hsi2c";
			status = "disabled";
			phandle = <0xaa>;
		};

		hsi2c@136a0000 {
			compatible = "samsung,exynos7-hsi2c";
			reg = <0x136a0000 0x1000>;
			interrupts = <0x00 0x1bf 0x04>;
			#address-cells = <0x01>;
			#size-cells = <0x00>;
			pinctrl-names = "default";
			pinctrl-0 = <0x16>;
			clocks = <0x07 0x09>;
			clock-names = "hsi2c";
			status = "disabled";
			phandle = <0xab>;
		};

		arm-pmu {
			compatible = "arm,cortex-a57-pmu\0arm,armv8-pmuv3";
			interrupts = <0x00 0x38 0x04 0x00 0x39 0x04 0x00 0x3a 0x04 0x00 0x3b 0x04>;
			interrupt-affinity = <0x17 0x18 0x19 0x1a>;
		};

		timer {
			compatible = "arm,armv8-timer";
			interrupts = <0x01 0x0d 0xff08 0x01 0x0e 0xff08 0x01 0x0b 0xff08 0x01 0x0a 0xff08>;
		};

		system-controller@105c0000 {
			compatible = "samsung,exynos7-pmu\0syscon";
			reg = <0x105c0000 0x5000>;
			phandle = <0x1b>;

			syscon-reboot {
				compatible = "syscon-reboot";
				regmap = <0x1b>;
				offset = <0x400>;
				mask = <0x01>;
				phandle = <0xac>;
			};
		};

		rtc@10590000 {
			compatible = "samsung,s3c6410-rtc";
			reg = <0x10590000 0x100>;
			interrupts = <0x00 0x163 0x04 0x00 0x164 0x04>;
			clocks = <0x1c 0x01 0x1d 0x00>;
			clock-names = "rtc\0rtc_src";
			status = "okay";
			phandle = <0xad>;
		};

		watchdog@101d0000 {
			compatible = "samsung,exynos7-wdt";
			reg = <0x101d0000 0x100>;
			interrupts = <0x00 0x6e 0x04>;
			clocks = <0x1e 0x03>;
			clock-names = "watchdog";
			samsung,syscon-phandle = <0x1b>;
			status = "okay";
			phandle = <0xae>;
		};

		mmc@15740000 {
			compatible = "samsung,exynos7-dw-mshc-smu";
			interrupts = <0x00 0xc9 0x04>;
			#address-cells = <0x01>;
			#size-cells = <0x00>;
			reg = <0x15740000 0x2000>;
			clocks = <0x1f 0x02 0x06 0x08>;
			clock-names = "biu\0ciu";
			fifo-depth = <0x40>;
			status = "okay";
			cap-mmc-highspeed;
			mmc-hs200-1_8v;
			non-removable;
			card-detect-delay = <0xc8>;
			clock-frequency = <0x2faf0800>;
			samsung,dw-mshc-ciu-div = <0x03>;
			samsung,dw-mshc-sdr-timing = <0x00 0x04>;
			samsung,dw-mshc-ddr-timing = <0x00 0x02>;
			pinctrl-names = "default";
			pinctrl-0 = <0x20 0x21 0x22 0x23 0x24 0x25>;
			bus-width = <0x08>;
			phandle = <0xaf>;
		};

		mmc@15750000 {
			compatible = "samsung,exynos7-dw-mshc";
			interrupts = <0x00 0xca 0x04>;
			#address-cells = <0x01>;
			#size-cells = <0x00>;
			reg = <0x15750000 0x2000>;
			clocks = <0x1f 0x01 0x06 0x07>;
			clock-names = "biu\0ciu";
			fifo-depth = <0x40>;
			status = "disabled";
			phandle = <0xb0>;
		};

		mmc@15560000 {
			compatible = "samsung,exynos7-dw-mshc-smu";
			interrupts = <0x00 0xd8 0x04>;
			#address-cells = <0x01>;
			#size-cells = <0x00>;
			reg = <0x15560000 0x2000>;
			clocks = <0x02 0x01 0x06 0x06>;
			clock-names = "biu\0ciu";
			fifo-depth = <0x40>;
			status = "okay";
			cap-sd-highspeed;
			card-detect-delay = <0xc8>;
			clock-frequency = <0x17d78400>;
			samsung,dw-mshc-ciu-div = <0x03>;
			samsung,dw-mshc-sdr-timing = <0x02 0x03>;
			samsung,dw-mshc-ddr-timing = <0x01 0x02>;
			pinctrl-names = "default";
			pinctrl-0 = <0x26 0x27 0x28 0x29 0x2a>;
			bus-width = <0x04>;
			vmmc-supply = <0x2b>;
			vqmmc-supply = <0x2c>;
			disable-wp;
			phandle = <0xb1>;
		};

		adc@13620000 {
			compatible = "samsung,exynos7-adc";
			reg = <0x13620000 0x100>;
			interrupts = <0x00 0x1c0 0x04>;
			clocks = <0x07 0x0c>;
			clock-names = "adc";
			#io-channel-cells = <0x01>;
			io-channel-ranges;
			status = "okay";
			phandle = <0xb2>;
		};

		pwm@136c0000 {
			compatible = "samsung,exynos4210-pwm";
			reg = <0x136c0000 0x100>;
			samsung,pwm-outputs = <0x00 0x01 0x02 0x03>;
			#pwm-cells = <0x03>;
			clocks = <0x07 0x0a>;
			clock-names = "timers";
			phandle = <0xb3>;
		};

		tmu@10060000 {
			compatible = "samsung,exynos7-tmu";
			reg = <0x10060000 0x200>;
			interrupts = <0x00 0x6c 0x04>;
			clocks = <0x1e 0x04 0x1e 0x05>;
			clock-names = "tmu_apbif\0tmu_sclk";
			#thermal-sensor-cells = <0x00>;
			phandle = <0x2d>;
		};

		thermal-zones {

			cluster0-thermal {
				polling-delay-passive = <0x00>;
				polling-delay = <0x00>;
				thermal-sensors = <0x2d>;
				phandle = <0xb4>;

				trips {

					cpu-alert-0 {
						temperature = <0x124f8>;
						hysteresis = <0x2710>;
						type = "passive";
					};

					cpu-alert-1 {
						temperature = <0x13880>;
						hysteresis = <0x2710>;
						type = "passive";
					};

					cpu-alert-2 {
						temperature = <0x14c08>;
						hysteresis = <0x2710>;
						type = "passive";
					};

					cpu-alert-3 {
						temperature = <0x15f90>;
						hysteresis = <0x2710>;
						type = "passive";
					};

					cpu-alert-4 {
						temperature = <0x17318>;
						hysteresis = <0x2710>;
						type = "passive";
					};

					cpu-alert-5 {
						temperature = <0x186a0>;
						hysteresis = <0x2710>;
						type = "passive";
					};

					cpu-alert-6 {
						temperature = <0x1adb0>;
						hysteresis = <0x2710>;
						type = "passive";
					};

					cpu-crit-0 {
						temperature = <0x1c138>;
						hysteresis = <0x00>;
						type = "critical";
					};
				};
			};
		};

		phy@15500000 {
			compatible = "samsung,exynos7-usbdrd-phy";
			reg = <0x15500000 0x100>;
			clocks = <0x02 0x03 0x02 0x08 0x02 0x06 0x02 0x07 0x02 0x05>;
			clock-names = "phy\0ref\0phy_pipe\0phy_utmi\0itp";
			samsung,pmu-syscon = <0x1b>;
			#phy-cells = <0x01>;
			vbus-supply = <0x2e>;
			vbus-boost-supply = <0x2f>;
			phandle = <0x30>;
		};

		usbdrd3 {
			compatible = "samsung,exynos7-dwusb3";
			clocks = <0x02 0x03 0x02 0x04 0x02 0x02>;
			clock-names = "usbdrd30\0usbdrd30_susp_clk\0usbdrd30_axius_clk";
			#address-cells = <0x01>;
			#size-cells = <0x01>;
			ranges;

			dwc3@15400000 {
				compatible = "snps,dwc3";
				reg = <0x15400000 0x10000>;
				interrupts = <0x00 0xdf 0x04>;
				phys = <0x30 0x00 0x30 0x01>;
				phy-names = "usb2-phy\0usb3-phy";
			};
		};
	};

	chosen {
		stdout-path = "/soc/serial@14c30000";
	};

	memory@40000000 {
		device_type = "memory";
		reg = <0x00 0x40000000 0x00 0xc0000000>;
	};

	regulator-usb30 {
		compatible = "regulator-fixed";
		regulator-name = "VBUS_5V";
		regulator-min-microvolt = <0x4c4b40>;
		regulator-max-microvolt = <0x4c4b40>;
		gpio = <0x31 0x01 0x00>;
		pinctrl-names = "default";
		pinctrl-0 = <0x32>;
		enable-active-high;
		phandle = <0x2e>;
	};

	regulator-usb3drd-boost {
		compatible = "regulator-fixed";
		regulator-name = "VUSB_VBUS_5V";
		regulator-min-microvolt = <0x4c4b40>;
		regulator-max-microvolt = <0x4c4b40>;
		gpio = <0x33 0x01 0x00>;
		pinctrl-names = "default";
		pinctrl-0 = <0x34>;
		enable-active-high;
		phandle = <0x2f>;
	};

};

&fin_pll {
	clock-frequency = <24000000>;
};

&serial_2 {
	status = "okay";
};

&rtc {
	status = "okay";
	clocks = <&clock_ccore PCLK_RTC>, <&s2mps15_osc S2MPS11_CLK_AP>;
	clock-names = "rtc", "rtc_src";
};

&watchdog {
	status = "okay";
};

&adc {
	status = "okay";
};

&hsi2c_4 {
	samsung,i2c-sda-delay = <100>;
	samsung,i2c-max-bus-freq = <200000>;
	status = "okay";

	s2mps15_pmic@66 {
		compatible = "samsung,s2mps15-pmic";
		reg = <0x66>;
		interrupts = <2 IRQ_TYPE_LEVEL_LOW>;
		interrupt-parent = <&gpa0>;
		pinctrl-names = "default";
		pinctrl-0 = <&pmic_irq>;
		wakeup-source;

		s2mps15_osc: clocks {
			compatible = "samsung,s2mps13-clk";
			#clock-cells = <1>;
			clock-output-names = "s2mps13_ap", "s2mps13_cp",
				"s2mps13_bt";
		};

		regulators {
			ldo1_reg: LDO1 {
				regulator-name = "vdd_ldo1";
				regulator-min-microvolt = <500000>;
				regulator-max-microvolt = <900000>;
				regulator-always-on;
				regulator-enable-ramp-delay = <125>;
			};

			ldo2_reg: LDO2 {
				regulator-name = "vqmmc-sdcard";
				regulator-min-microvolt = <1620000>;
				regulator-max-microvolt = <3300000>;
				regulator-always-on;
				regulator-enable-ramp-delay = <125>;
			};

			ldo3_reg: LDO3 {
				regulator-name = "vdd_ldo3";
				regulator-min-microvolt = <1620000>;
				regulator-max-microvolt = <1980000>;
				regulator-always-on;
				regulator-boot-on;
				regulator-enable-ramp-delay = <125>;
			};

			ldo4_reg: LDO4 {
				regulator-name = "vdd_ldo4";
				regulator-min-microvolt = <800000>;
				regulator-max-microvolt = <1110000>;
				regulator-always-on;
				regulator-enable-ramp-delay = <125>;
			};

			ldo5_reg: LDO5 {
				regulator-name = "vdd_ldo5";
				regulator-min-microvolt = <1620000>;
				regulator-max-microvolt = <1980000>;
				regulator-always-on;
				regulator-enable-ramp-delay = <125>;
			};

			ldo6_reg: LDO6 {
				regulator-name = "vdd_ldo6";
				regulator-min-microvolt = <2250000>;
				regulator-max-microvolt = <3300000>;
				regulator-enable-ramp-delay = <125>;
			};

			ldo7_reg: LDO7 {
				regulator-name = "vdd_ldo7";
				regulator-min-microvolt = <700000>;
				regulator-max-microvolt = <1150000>;
				regulator-enable-ramp-delay = <125>;
				regulator-always-on;
			};

			ldo8_reg: LDO8 {
				regulator-name = "vdd_ldo8";
				regulator-min-microvolt = <700000>;
				regulator-max-microvolt = <1000000>;
				regulator-enable-ramp-delay = <125>;
			};

			ldo9_reg: LDO9 {
				regulator-name = "vdd_ldo9";
				regulator-min-microvolt = <700000>;
				regulator-max-microvolt = <1000000>;
				regulator-enable-ramp-delay = <125>;
			};

			ldo10_reg: LDO10 {
				regulator-name = "vdd_ldo10";
				regulator-min-microvolt = <700000>;
				regulator-max-microvolt = <1000000>;
				regulator-enable-ramp-delay = <125>;
			};

			ldo11_reg: LDO11 {
				regulator-name = "vdd_ldo11";
				regulator-min-microvolt = <1000000>;
				regulator-max-microvolt = <1300000>;
				regulator-always-on;
				regulator-enable-ramp-delay = <125>;
			};

			ldo12_reg: LDO12 {
				regulator-name = "vdd_ldo12";
				regulator-min-microvolt = <1000000>;
				regulator-max-microvolt = <1300000>;
				regulator-enable-ramp-delay = <125>;
			};

			ldo13_reg: LDO13 {
				regulator-name = "vdd_ldo13";
				regulator-min-microvolt = <1000000>;
				regulator-max-microvolt = <1300000>;
				regulator-always-on;
				regulator-enable-ramp-delay = <125>;
			};

			ldo14_reg: LDO14 {
				regulator-name = "vdd_ldo14";
				regulator-min-microvolt = <1800000>;
				regulator-max-microvolt = <3375000>;
				regulator-enable-ramp-delay = <125>;
			};

			ldo17_reg: LDO17 {
				regulator-name = "vmmc-sdcard";
				regulator-min-microvolt = <1800000>;
				regulator-max-microvolt = <3375000>;
				regulator-enable-ramp-delay = <125>;
			};

			ldo18_reg: LDO18 {
				regulator-name = "vdd_ldo18";
				regulator-min-microvolt = <1500000>;
				regulator-max-microvolt = <2275000>;
				regulator-enable-ramp-delay = <125>;
			};

			ldo19_reg: LDO19 {
				regulator-name = "vdd_ldo19";
				regulator-min-microvolt = <1800000>;
				regulator-max-microvolt = <3375000>;
				regulator-enable-ramp-delay = <125>;
			};

			ldo21_reg: LDO21 {
				regulator-name = "vdd_ldo21";
				regulator-min-microvolt = <1800000>;
				regulator-max-microvolt = <3375000>;
				regulator-enable-ramp-delay = <125>;
			};

			ldo23_reg: LDO23 {
				regulator-name = "vdd_ldo23";
				regulator-min-microvolt = <1500000>;
				regulator-max-microvolt = <2275000>;
				regulator-enable-ramp-delay = <125>;
			};

			ldo25_reg: LDO25 {
				regulator-name = "vdd_ldo25";
				regulator-min-microvolt = <1800000>;
				regulator-max-microvolt = <3375000>;
				regulator-enable-ramp-delay = <125>;
			};

			ldo26_reg: LDO26 {
				regulator-name = "vdd_ldo26";
				regulator-min-microvolt = <700000>;
				regulator-max-microvolt = <1470000>;
				regulator-enable-ramp-delay = <125>;
			};

			ldo27_reg: LDO27 {
				regulator-name = "vdd_ldo27";
				regulator-min-microvolt = <1500000>;
				regulator-max-microvolt = <2275000>;
				regulator-enable-ramp-delay = <125>;
			};

			buck1_reg: BUCK1 {
				regulator-name = "vdd_mif";
				regulator-min-microvolt = <500000>;
				regulator-max-microvolt = <1200000>;
				regulator-always-on;
				regulator-boot-on;
				regulator-ramp-delay = <25000>;
				regulator-enable-ramp-delay = <250>;
			};

			buck2_reg: BUCK2 {
				regulator-name = "vdd_atlas";
				regulator-min-microvolt = <500000>;
				regulator-max-microvolt = <1200000>;
				regulator-always-on;
				regulator-boot-on;
				regulator-ramp-delay = <12500>;
				regulator-enable-ramp-delay = <250>;
			};

			buck4_reg: BUCK4 {
				regulator-name = "vdd_int";
				regulator-min-microvolt = <500000>;
				regulator-max-microvolt = <1200000>;
				regulator-always-on;
				regulator-boot-on;
				regulator-ramp-delay = <12500>;
				regulator-enable-ramp-delay = <250>;
			};

			buck5_reg: BUCK5 {
				regulator-name = "vdd_buck5";
				regulator-min-microvolt = <500000>;
				regulator-max-microvolt = <1300000>;
				regulator-ramp-delay = <25000>;
				regulator-enable-ramp-delay = <250>;
			};

			buck6_reg: BUCK6 {
				regulator-name = "vdd_g3d";
				regulator-min-microvolt = <500000>;
				regulator-max-microvolt = <1400000>;
				regulator-ramp-delay = <12500>;
				regulator-enable-ramp-delay = <250>;
			};

			buck7_reg: BUCK7 {
				regulator-name = "vdd_buck7";
				regulator-min-microvolt = <1000000>;
				regulator-max-microvolt = <1500000>;
				regulator-always-on;
				regulator-ramp-delay = <25000>;
				regulator-enable-ramp-delay = <250>;
			};

			buck8_reg: BUCK8 {
				regulator-name = "vdd_buck8";
				regulator-min-microvolt = <1000000>;
				regulator-max-microvolt = <1500000>;
				regulator-always-on;
				regulator-ramp-delay = <25000>;
				regulator-enable-ramp-delay = <250>;
			};

			buck9_reg: BUCK9 {
				regulator-name = "vdd_buck9";
				regulator-min-microvolt = <1800000>;
				regulator-max-microvolt = <2100000>;
				regulator-always-on;
				regulator-ramp-delay = <25000>;
				regulator-enable-ramp-delay = <250>;
			};

			buck10_reg: BUCK10 {
				regulator-name = "vdd_buck10";
				regulator-min-microvolt = <1000000>;
				regulator-max-microvolt = <3000000>;
				regulator-always-on;
				regulator-ramp-delay = <25000>;
				regulator-enable-ramp-delay = <250>;
			};
		};
	};
};
